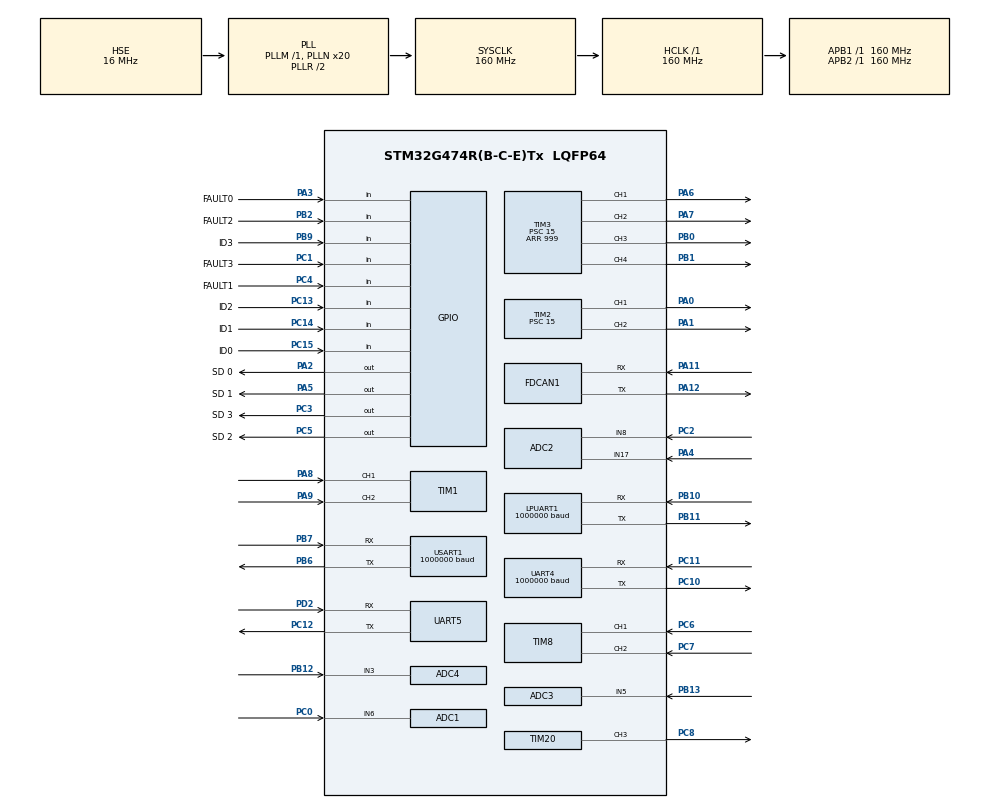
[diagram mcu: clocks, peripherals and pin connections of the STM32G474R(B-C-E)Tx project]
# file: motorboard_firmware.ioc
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ADC1.Channel-0\#ChannelRegularConversion=ADC_CHANNEL_6
ADC1.NbrOfConversionFlag=1
ADC1.OffsetNumber-0\#ChannelRegularConversion=ADC_OFFSET_NONE
ADC1.Rank-0\#ChannelRegularConversion=1
ADC1.SamplingTime-0\#ChannelRegularConversion=ADC_SAMPLETIME_2CYCLES_5
ADC1.master=1
ADC2.Channel-0\#ChannelRegularConversion=ADC_CHANNEL_17
ADC2.NbrOfConversionFlag=1
ADC2.OffsetNumber-0\#ChannelRegularConversion=ADC_OFFSET_NONE
ADC2.Rank-0\#ChannelRegularConversion=1
ADC2.SamplingTime-0\#ChannelRegularConversion=ADC_SAMPLETIME_2CYCLES_5
ADC3.Channel-0\#ChannelRegularConversion=ADC_CHANNEL_5
ADC3.NbrOfConversionFlag=1
ADC3.OffsetNumber-0\#ChannelRegularConversion=ADC_OFFSET_NONE
ADC3.Rank-0\#ChannelRegularConversion=1
ADC3.SamplingTime-0\#ChannelRegularConversion=ADC_SAMPLETIME_2CYCLES_5
ADC3.master=1
ADC4.Channel-0\#ChannelRegularConversion=ADC_CHANNEL_3
ADC4.NbrOfConversionFlag=1
ADC4.OffsetNumber-0\#ChannelRegularConversion=ADC_OFFSET_NONE
ADC4.Rank-0\#ChannelRegularConversion=1
ADC4.SamplingTime-0\#ChannelRegularConversion=ADC_SAMPLETIME_2CYCLES_5
Dma.Request0=TIM20_CH3
Dma.TIM20_CH3.0.Direction=DMA_MEMORY_TO_PERIPH
Dma.TIM20_CH3.0.EventEnable=DISABLE
Dma.TIM20_CH3.0.Instance=DMA1_Channel1
Dma.TIM20_CH3.0.MemDataAlignment=DMA_MDATAALIGN_WORD
Dma.TIM20_CH3.0.MemInc=DMA_MINC_ENABLE
Dma.TIM20_CH3.0.Mode=DMA_CIRCULAR
Dma.TIM20_CH3.0.PeriphDataAlignment=DMA_PDATAALIGN_HALFWORD
Dma.TIM20_CH3.0.PeriphInc=DMA_PINC_DISABLE
Dma.TIM20_CH3.0.Polarity=HAL_DMAMUX_REQ_GEN_RISING
Dma.TIM20_CH3.0.Priority=DMA_PRIORITY_MEDIUM
Dma.TIM20_CH3.0.RequestNumber=1
Dma.TIM20_CH3.0.SignalID=NONE
Dma.TIM20_CH3.0.SyncEnable=DISABLE
Dma.TIM20_CH3.0.SyncPolarity=HAL_DMAMUX_SYNC_NO_EVENT
Dma.TIM20_CH3.0.SyncRequestNumber=1
Dma.TIM20_CH3.0.SyncSignalID=NONE
FDCAN1.AutoRetransmission=ENABLE
FDCAN1.CalculateBaudRateNominal=1000000
FDCAN1.CalculateTimeBitNominal=1000
FDCAN1.CalculateTimeQuantumNominal=25.0
FDCAN1.DataPrescaler=4
FDCAN1.DataSyncJumpWidth=10
FDCAN1.DataTimeSeg1=9
FDCAN1.DataTimeSeg2=10
FDCAN1.ExtFiltersNbr=0
FDCAN1.FrameFormat=FDCAN_FRAME_FD_BRS
FDCAN1.Mode=FDCAN_MODE_NORMAL
FDCAN1.NominalPrescaler=4
FDCAN1.NominalSyncJumpWidth=10
FDCAN1.NominalTimeSeg1=29
FDCAN1.NominalTimeSeg2=10
FDCAN1.ProtocolException=ENABLE
FDCAN1.StdFiltersNbr=2
FREERTOS.Tasks01=defaultTask,24,256,StartDefaultTask,As weak,NULL,Static,defaultTaskBuffer,defaultTaskControlBlock
FREERTOS.Timers01=controlTimer,controlCallback,osTimerPeriodic,As weak,NULL,Dynamic,NULL
FREERTOS.configTIMER_TASK_STACK_DEPTH=1000
LPUART1.BaudRate=1000000
Mcu.Family=STM32G4
Mcu.Name=STM32G474R(B-C-E)Tx
Mcu.Package=LQFP64
NVIC.DMA1_Channel1_IRQn=true\:5\:0\:false\:false\:true\:true\:false\:true\:true
NVIC.FDCAN1_IT0_IRQn=true\:5\:0\:false\:false\:true\:true\:true\:true\:true
NVIC.PriorityGroup=NVIC_PRIORITYGROUP_4
NVIC.TIM6_DAC_IRQn=true\:15\:0\:false\:false\:true\:false\:false\:true\:true
NVIC.TimeBase=TIM6_DAC_IRQn
NVIC.TimeBaseIP=TIM6
PA0.Signal=S_TIM2_CH1
PA1.Signal=S_TIM2_CH2
PA11.GPIO_Speed=GPIO_SPEED_FREQ_VERY_HIGH
PA11.Mode=FDCAN_Activate
PA11.Signal=FDCAN1_RX
PA12.GPIO_Speed=GPIO_SPEED_FREQ_VERY_HIGH
PA12.Mode=FDCAN_Activate
PA12.Signal=FDCAN1_TX
PA13.Mode=Trace_Asynchronous_SW
PA13.Signal=SYS_JTMS-SWDIO
PA14.Mode=Trace_Asynchronous_SW
PA14.Signal=SYS_JTCK-SWCLK
PA2.GPIO_Label=SD 0
PA2.Signal=GPIO_Output
PA3.GPIO_Label=FAULT0
PA3.Signal=GPIO_Input
PA4.Mode=IN17-Single-Ended
PA4.Signal=ADC2_IN17
PA5.GPIO_Label=SD 1
PA5.Signal=GPIO_Output
PA6.Signal=S_TIM3_CH1
PA7.Signal=S_TIM3_CH2
PA8.Signal=S_TIM1_CH1
PA9.Signal=S_TIM1_CH2
PB0.Signal=S_TIM3_CH3
PB1.Signal=S_TIM3_CH4
PB10.Mode=Asynchronous
PB10.Signal=LPUART1_RX
PB11.Mode=Asynchronous
PB11.Signal=LPUART1_TX
PB12.Mode=IN3-Single-Ended
PB12.Signal=ADC4_IN3
PB13.Mode=IN5-Single-Ended
PB13.Signal=ADC3_IN5
PB2.GPIO_Label=FAULT2
PB2.Signal=GPIO_Input
PB3.Mode=Trace_Asynchronous_SW
PB3.Signal=SYS_JTDO-SWO
PB6.Mode=Asynchronous
PB6.Signal=USART1_TX
PB7.Mode=Asynchronous
PB7.Signal=USART1_RX
PB9.GPIO_Label=ID3
PB9.GPIO_PuPd=GPIO_PULLUP
PB9.Signal=GPIO_Input
PC0.Mode=IN6-Single-Ended
PC0.Signal=ADC1_IN6
PC1.GPIO_Label=FAULT3
PC1.Signal=GPIO_Input
PC10.Mode=Asynchronous
PC10.Signal=UART4_TX
PC11.Mode=Asynchronous
PC11.Signal=UART4_RX
PC12.Mode=Asynchronous
PC12.Signal=UART5_TX
PC13.GPIO_Label=ID2
PC13.GPIO_PuPd=GPIO_PULLUP
PC13.Signal=GPIO_Input
PC14-OSC32_IN.GPIO_Label=ID1
PC14-OSC32_IN.GPIO_PuPd=GPIO_PULLUP
PC14-OSC32_IN.Signal=GPIO_Input
PC15-OSC32_OUT.GPIO_Label=ID0
PC15-OSC32_OUT.GPIO_PuPd=GPIO_PULLUP
PC15-OSC32_OUT.Signal=GPIO_Input
PC2.Mode=IN8-Single-Ended
PC2.Signal=ADC2_IN8
PC3.GPIO_Label=SD 3
PC3.Signal=GPIO_Output
PC4.GPIO_Label=FAULT1
PC4.Signal=GPIO_Input
PC5.GPIO_Label=SD 2
PC5.Signal=GPIO_Output
PC6.Signal=S_TIM8_CH1
PC7.Signal=S_TIM8_CH2
PC8.Signal=S_TIM20_CH3
PD2.Mode=Asynchronous
PD2.Signal=UART5_RX
PF0-OSC_IN.Mode=HSE-External-Oscillator
PF0-OSC_IN.Signal=RCC_OSC_IN
PF1-OSC_OUT.Mode=HSE-External-Oscillator
PF1-OSC_OUT.Signal=RCC_OSC_OUT
ProjectManager.HeapSize=0x200
ProjectManager.StackSize=0x400
ProjectManager.TargetToolchain=CMake
RCC.ADC12Freq_Value=160000000
RCC.ADC345Freq_Value=160000000
RCC.AHBFreq_Value=160000000
RCC.APB1Freq_Value=160000000
RCC.APB1TimFreq_Value=160000000
RCC.APB2Freq_Value=160000000
RCC.APB2TimFreq_Value=160000000
RCC.CortexFreq_Value=160000000
RCC.EXTERNAL_CLOCK_VALUE=12288000
RCC.EnbaleCSS=true
RCC.HCLKFreq_Value=160000000
RCC.HSE_VALUE=16000000
RCC.HSI48_VALUE=48000000
RCC.HSI_VALUE=16000000
RCC.LPTIM1CLockSelection=RCC_LPTIM1CLKSOURCE_HSI
RCC.LSE_VALUE=32768
RCC.PLLN=20
RCC.PLLSourceVirtual=RCC_PLLSOURCE_HSE
RCC.SYSCLKFreq_VALUE=160000000
RCC.SYSCLKSource=RCC_SYSCLKSOURCE_PLLCLK
RCC.USBFreq_Value=160000000
RCC.VCOOutputFreq_Value=320000000
SH.S_TIM1_CH1.0=TIM1_CH1,Encoder_Interface
SH.S_TIM1_CH2.0=TIM1_CH2,Encoder_Interface
SH.S_TIM20_CH3.0=TIM20_CH3,PWM Generation3 CH3
SH.S_TIM2_CH1.0=TIM2_CH1,PWM Generation1 CH1
SH.S_TIM2_CH2.0=TIM2_CH2,PWM Generation2 CH2
SH.S_TIM3_CH1.0=TIM3_CH1,PWM Generation1 CH1
SH.S_TIM3_CH2.0=TIM3_CH2,PWM Generation2 CH2
SH.S_TIM3_CH3.0=TIM3_CH3,PWM Generation3 CH3
SH.S_TIM3_CH4.0=TIM3_CH4,PWM Generation4 CH4
SH.S_TIM8_CH1.0=TIM8_CH1,Encoder_Interface
SH.S_TIM8_CH2.0=TIM8_CH2,Encoder_Interface
SYS.VoltageScaling=SYSCFG_VREFBUF_VOLTAGE_SCALE1
TIM2.Channel-PWM\ Generation1\ CH1=TIM_CHANNEL_1
TIM2.Channel-PWM\ Generation2\ CH2=TIM_CHANNEL_2
TIM2.PeriodNoDither=999
TIM2.Prescaler=15
TIM20.Channel-PWM\ Generation3\ CH3=TIM_CHANNEL_3
TIM20.OCFastMode_PWM-PWM\ Generation3\ CH3=TIM_OCFAST_ENABLE
TIM20.PeriodNoDither=19
TIM20.Prescaler=9
TIM3.Channel-PWM\ Generation1\ CH1=TIM_CHANNEL_1
TIM3.Channel-PWM\ Generation2\ CH2=TIM_CHANNEL_2
TIM3.Channel-PWM\ Generation3\ CH3=TIM_CHANNEL_3
TIM3.Channel-PWM\ Generation4\ CH4=TIM_CHANNEL_4
TIM3.PeriodNoDither=999
TIM3.Prescaler=15
UART4.BaudRate=1000000
UART4.OneBitSampling=UART_ONE_BIT_SAMPLE_DISABLE
USART1.BaudRate=1000000
USART1.VirtualMode-Asynchronous=VM_ASYNC
VP_FREERTOS_VS_CMSIS_V2.Mode=CMSIS_V2
VP_SYS_VS_DBSignals.Mode=DisableDeadBatterySignals
VP_SYS_VS_tim6.Mode=TIM6
VP_TIM17_VS_ClockSourceINT.Mode=Enable_Timer
VREF+.Mode=InternalMode
VREF+.Signal=VREFBUF_OUT
board=custom

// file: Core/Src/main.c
/* USER CODE BEGIN Header */
/**
  ******************************************************************************
  * @file           : main.c
  * @brief          : Main program body
  ******************************************************************************
  * @attention
  *
  * Copyright (c) 2025 STMicroelectronics.
  * All rights reserved.
  *
  * This software is licensed under terms that can be found in the LICENSE file
  * in the root directory of this software component.
  * If no LICENSE file comes with this software, it is provided AS-IS.
  *
  ******************************************************************************
  */
/* USER CODE END Header */
#include "main.h"
#include "cmsis_os.h"
#include "adc.h"
#include "dma.h"
#include "fdcan.h"
#include "usart.h"
#include "tim.h"
#include "gpio.h"

/* USER CODE BEGIN Includes */
#include <stdio.h>
/* USER CODE END Includes */

/* USER CODE BEGIN PM */
int _write(int file, char *ptr, int len)
{
  HAL_UART_Transmit(&huart5, (uint8_t *)ptr,len,10);
  return len;
}
/* USER CODE END PM */

void SystemClock_Config(void);
void MX_FREERTOS_Init(void);
/* USER CODE BEGIN PFP */
int can_id;
/* USER CODE END PFP */

int main(void)
{

  /* MCU Configuration--------------------------------------------------------*/

  /* Reset of all peripherals, Initializes the Flash interface and the Systick. */
  HAL_Init();

  /* Configure the system clock */
  SystemClock_Config();

  /* Initialize all configured peripherals */
  MX_GPIO_Init();
  MX_DMA_Init();
  MX_ADC2_Init();
  MX_ADC3_Init();
  MX_ADC4_Init();
  MX_FDCAN1_Init();
  MX_TIM1_Init();
  MX_TIM2_Init();
  MX_TIM3_Init();
  MX_TIM8_Init();
  MX_UART5_Init();
  MX_ADC1_Init();
  MX_USART1_UART_Init();
  MX_TIM17_Init();
  MX_TIM20_Init();
  MX_UART4_Init();
  MX_LPUART1_UART_Init();
  /* USER CODE BEGIN 2 */
  setbuf(stdout, NULL);
  /* USER CODE END 2 */

  /* Init scheduler */
  osKernelInitialize();

  /* Call init function for freertos objects (in cmsis_os2.c) */
  MX_FREERTOS_Init();

  /* Start scheduler */
  osKernelStart();

  /* We should never get here as control is now taken by the scheduler */

  /* Infinite loop */
  while (1)
  {

  }
}

void SystemClock_Config(void)
{
  RCC_OscInitTypeDef RCC_OscInitStruct = {0};
  RCC_ClkInitTypeDef RCC_ClkInitStruct = {0};

  /** Configure the main internal regulator output voltage
  */
  HAL_PWREx_ControlVoltageScaling(PWR_REGULATOR_VOLTAGE_SCALE1_BOOST);

  /** Initializes the RCC Oscillators according to the specified parameters
  * in the RCC_OscInitTypeDef structure.
  */
  RCC_OscInitStruct.OscillatorType = RCC_OSCILLATORTYPE_HSE;
  RCC_OscInitStruct.HSEState = RCC_HSE_ON;
  RCC_OscInitStruct.PLL.PLLState = RCC_PLL_ON;
  RCC_OscInitStruct.PLL.PLLSource = RCC_PLLSOURCE_HSE;
  RCC_OscInitStruct.PLL.PLLM = RCC_PLLM_DIV1;
  RCC_OscInitStruct.PLL.PLLN = 20;
  RCC_OscInitStruct.PLL.PLLP = RCC_PLLP_DIV2;
  RCC_OscInitStruct.PLL.PLLQ = RCC_PLLQ_DIV2;
  RCC_OscInitStruct.PLL.PLLR = RCC_PLLR_DIV2;
  if (HAL_RCC_OscConfig(&RCC_OscInitStruct) != HAL_OK)
  {
    Error_Handler();
  }

  /** Initializes the CPU, AHB and APB buses clocks
  */
  RCC_ClkInitStruct.ClockType = RCC_CLOCKTYPE_HCLK|RCC_CLOCKTYPE_SYSCLK
                              |RCC_CLOCKTYPE_PCLK1|RCC_CLOCKTYPE_PCLK2;
  RCC_ClkInitStruct.SYSCLKSource = RCC_SYSCLKSOURCE_PLLCLK;
  RCC_ClkInitStruct.AHBCLKDivider = RCC_SYSCLK_DIV1;
  RCC_ClkInitStruct.APB1CLKDivider = RCC_HCLK_DIV1;
  RCC_ClkInitStruct.APB2CLKDivider = RCC_HCLK_DIV1;

  if (HAL_RCC_ClockConfig(&RCC_ClkInitStruct, FLASH_LATENCY_4) != HAL_OK)
  {
    Error_Handler();
  }

  /** Enables the Clock Security System
  */
  HAL_RCC_EnableCSS();
}

void HAL_TIM_PeriodElapsedCallback(TIM_HandleTypeDef *htim)
{
  if (htim->Instance == TIM6)
  {
    HAL_IncTick();
  }
}

void Error_Handler(void)
{
  __disable_irq();
  while (1)
  {
  }
}

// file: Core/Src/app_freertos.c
/* USER CODE BEGIN Header */
/**
  ******************************************************************************
  * File Name          : app_freertos.c
  * Description        : Code for freertos applications
  ******************************************************************************
  * @attention
  *
  * Copyright (c) 2025 STMicroelectronics.
  * All rights reserved.
  *
  * This software is licensed under terms that can be found in the LICENSE file
  * in the root directory of this software component.
  * If no LICENSE file comes with this software, it is provided AS-IS.
  *
  ******************************************************************************
  */
/* USER CODE END Header */

#include "FreeRTOS.h"
#include "task.h"
#include "main.h"
#include "cmsis_os.h"

typedef StaticTask_t osStaticThreadDef_t;

/* Definitions for defaultTask */
osThreadId_t defaultTaskHandle;
uint32_t defaultTaskBuffer[ 256 ];
osStaticThreadDef_t defaultTaskControlBlock;
const osThreadAttr_t defaultTask_attributes = {
  .name = "defaultTask",
  .stack_mem = &defaultTaskBuffer[0],
  .stack_size = sizeof(defaultTaskBuffer),
  .cb_mem = &defaultTaskControlBlock,
  .cb_size = sizeof(defaultTaskControlBlock),
  .priority = (osPriority_t) osPriorityNormal,
};
/* Definitions for controlTimer */
osTimerId_t controlTimerHandle;
const osTimerAttr_t controlTimer_attributes = {
  .name = "controlTimer"
};

void StartDefaultTask(void *argument);
void controlCallback(void *argument);

void MX_FREERTOS_Init(void); /* (MISRA C 2004 rule 8.1) */

void MX_FREERTOS_Init(void) {

  /* Create the timer(s) */
  /* creation of controlTimer */
  controlTimerHandle = osTimerNew(controlCallback, osTimerPeriodic, NULL, &controlTimer_attributes);

  /* Create the thread(s) */
  /* creation of defaultTask */
  defaultTaskHandle = osThreadNew(StartDefaultTask, NULL, &defaultTask_attributes);

}

__weak void StartDefaultTask(void *argument)
{
  for(;;)
  {
    osDelay(1);
  }
}

/* controlCallback function */
__weak void controlCallback(void *argument)
{
}
